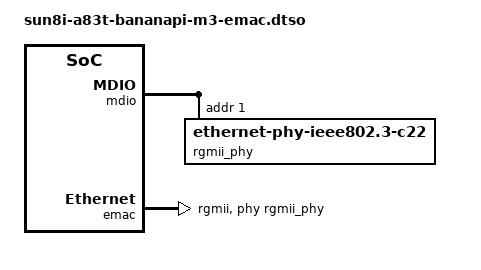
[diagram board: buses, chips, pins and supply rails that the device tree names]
/dts-v1/;
/plugin/;

/ {
	compatible = "sinovoip,bpi-m3";

	fragment@0 {
		target = <&mdio>;
		__overlay__ {
			rgmii_phy: ethernet-phy@1 {
				compatible = "ethernet-phy-ieee802.3-c22";
				reg = <0x1>;
			};
		};
	};

	fragment@1 {
		target = <&emac>;
		__overlay__ {
			pinctrl-names = "default";
			pinctrl-0 = <&emac_rgmii_pins>;
			phy-handle = <&rgmii_phy>;
			phy-mode = "rgmii";
			rx-delay = <0x7>;
			tx-delay = <0x7>;
			status = "okay";
		};
	};
};
